VERSION ""

NS_ :

BS_:

BU_: Engine ECU

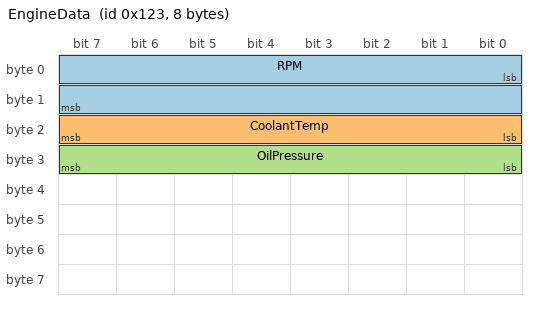
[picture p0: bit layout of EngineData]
BO_ 291 EngineData: 8 Engine
 SG_ RPM : 0|16@1+ (0.125,0) [0|8000] "rpm" ECU
 SG_ CoolantTemp : 16|8@1+ (1,-40) [-40|215] "degC" ECU
 SG_ OilPressure : 24|8@1+ (4,0) [0|1000] "kPa" ECU

BO_ 512 ControlCmd: 3 ECU
 SG_ GearReq : 0|4@0+ (1,0) [0|8] "" Engine
 SG_ Enable : 4|1@0+ (1,0) [0|1] "" Engine

VAL_ 512 GearReq 0 "Park" 1 "Reverse" 2 "Neutral" 3 "Drive" ;
